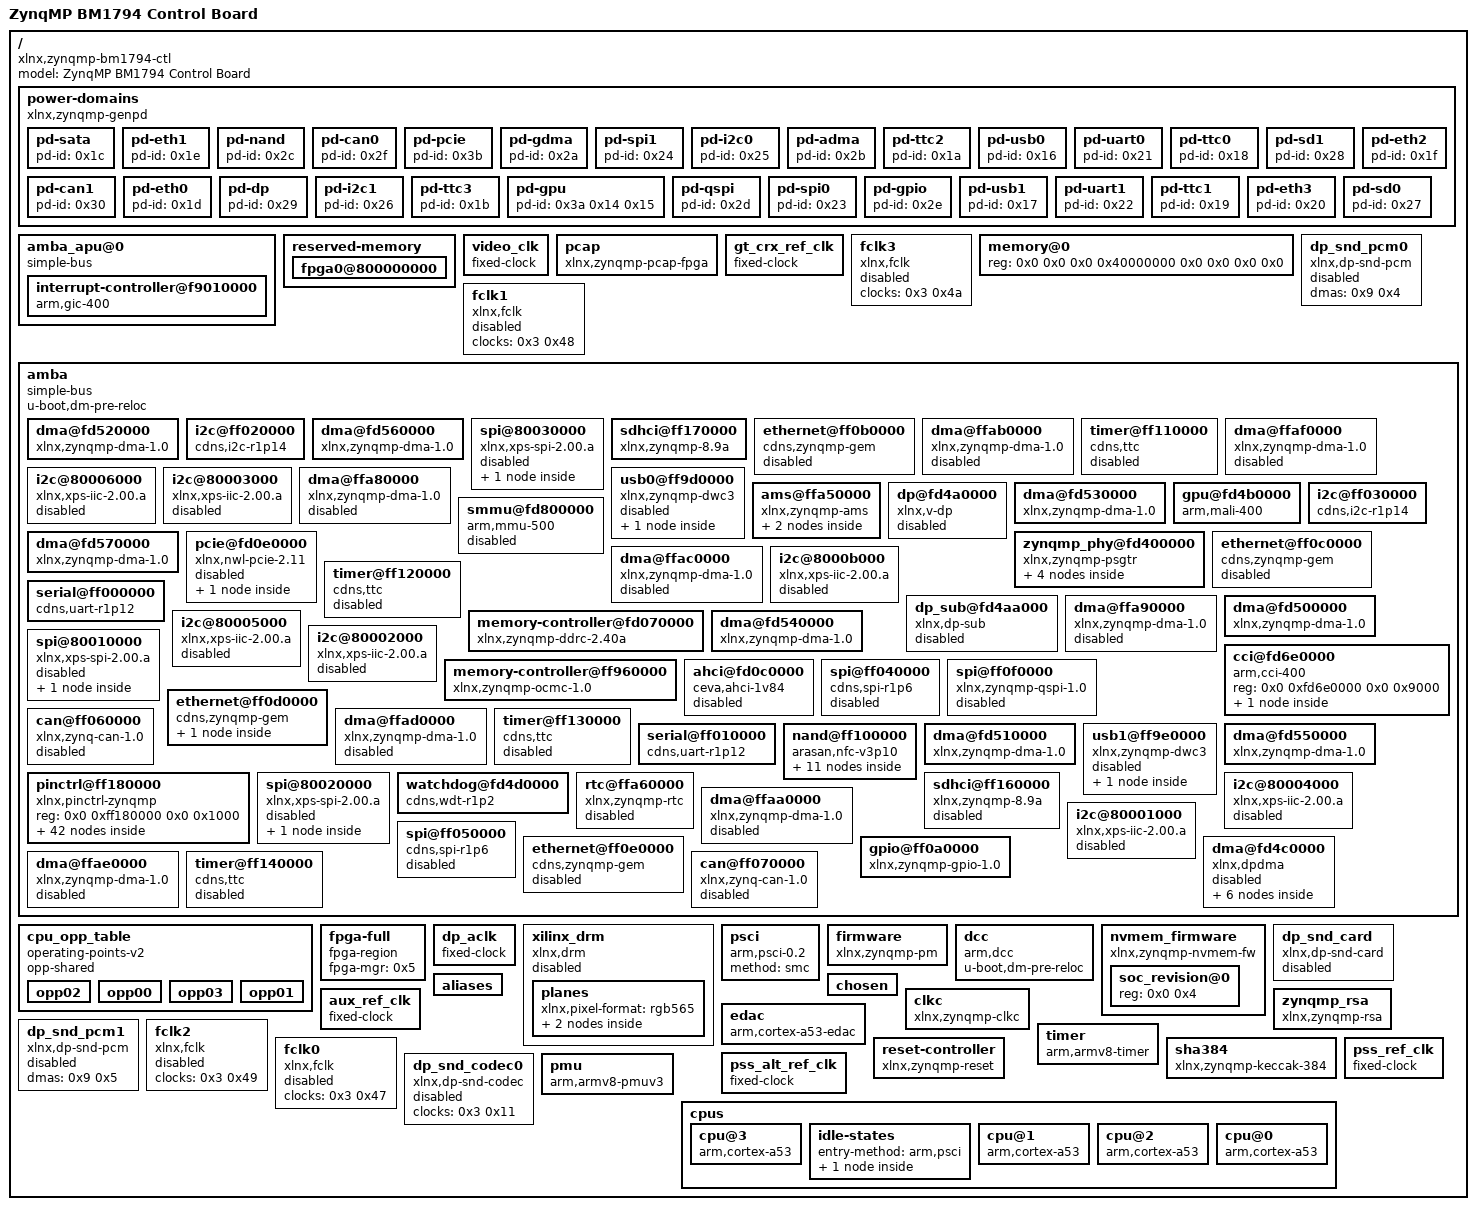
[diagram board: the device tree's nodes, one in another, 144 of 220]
/dts-v1/;

/ {
	compatible = "xlnx,zynqmp-bm1794-ctl", "xlnx,zynqmp";
	model = "ZynqMP BM1794 Control Board";
	#address-cells = <0x2>;
	#size-cells = <0x2>;

	power-domains {
		compatible = "xlnx,zynqmp-genpd";

		pd-sata {
			phandle = <0x28>;
			pd-id = <0x1c>;
			linux,phandle = <0x28>;
			#power-domain-cells = <0x0>;
		};

		pd-eth1 {
			phandle = <0x14>;
			pd-id = <0x1e>;
			linux,phandle = <0x14>;
			#power-domain-cells = <0x0>;
		};

		pd-nand {
			phandle = <0x12>;
			pd-id = <0x2c>;
			linux,phandle = <0x12>;
			#power-domain-cells = <0x0>;
		};

		pd-can0 {
			phandle = <0xc>;
			pd-id = <0x2f>;
			linux,phandle = <0xc>;
			#power-domain-cells = <0x0>;
		};

		pd-pcie {
			phandle = <0x24>;
			pd-id = <0x3b>;
			linux,phandle = <0x24>;
			#power-domain-cells = <0x0>;
		};

		pd-gdma {
			phandle = <0xf>;
			pd-id = <0x2a>;
			linux,phandle = <0xf>;
			#power-domain-cells = <0x0>;
		};

		pd-spi1 {
			phandle = <0x2f>;
			pd-id = <0x24>;
			linux,phandle = <0x2f>;
			#power-domain-cells = <0x0>;
		};

		pd-i2c0 {
			phandle = <0x1b>;
			pd-id = <0x25>;
			linux,phandle = <0x1b>;
			#power-domain-cells = <0x0>;
		};

		pd-adma {
			phandle = <0x11>;
			pd-id = <0x2b>;
			linux,phandle = <0x11>;
			#power-domain-cells = <0x0>;
		};

		pd-ttc2 {
			phandle = <0x32>;
			pd-id = <0x1a>;
			linux,phandle = <0x32>;
			#power-domain-cells = <0x0>;
		};

		pd-usb0 {
			phandle = <0x38>;
			pd-id = <0x16>;
			linux,phandle = <0x38>;
			#power-domain-cells = <0x0>;
		};

		pd-uart0 {
			phandle = <0x34>;
			pd-id = <0x21>;
			linux,phandle = <0x34>;
			#power-domain-cells = <0x0>;
		};

		pd-ttc0 {
			phandle = <0x30>;
			pd-id = <0x18>;
			linux,phandle = <0x30>;
			#power-domain-cells = <0x0>;
		};

		pd-sd1 {
			phandle = <0x2c>;
			pd-id = <0x28>;
			linux,phandle = <0x2c>;
			#power-domain-cells = <0x0>;
		};

		pd-eth2 {
			phandle = <0x15>;
			pd-id = <0x1f>;
			linux,phandle = <0x15>;
			#power-domain-cells = <0x0>;
		};

		pd-can1 {
			phandle = <0xd>;
			pd-id = <0x30>;
			linux,phandle = <0xd>;
			#power-domain-cells = <0x0>;
		};

		pd-eth0 {
			phandle = <0x13>;
			pd-id = <0x1d>;
			linux,phandle = <0x13>;
			#power-domain-cells = <0x0>;
		};

		pd-dp {
			phandle = <0x3a>;
			pd-id = <0x29>;
			linux,phandle = <0x3a>;
			#power-domain-cells = <0x0>;
		};

		pd-i2c1 {
			phandle = <0x1f>;
			pd-id = <0x26>;
			linux,phandle = <0x1f>;
			#power-domain-cells = <0x0>;
		};

		pd-ttc3 {
			phandle = <0x33>;
			pd-id = <0x1b>;
			linux,phandle = <0x33>;
			#power-domain-cells = <0x0>;
		};

		pd-gpu {
			phandle = <0x10>;
			pd-id = <0x3a 0x14 0x15>;
			linux,phandle = <0x10>;
			#power-domain-cells = <0x0>;
		};

		pd-qspi {
			phandle = <0x25>;
			pd-id = <0x2d>;
			linux,phandle = <0x25>;
			#power-domain-cells = <0x0>;
		};

		pd-spi0 {
			phandle = <0x2e>;
			pd-id = <0x23>;
			linux,phandle = <0x2e>;
			#power-domain-cells = <0x0>;
		};

		pd-gpio {
			phandle = <0x19>;
			pd-id = <0x2e>;
			linux,phandle = <0x19>;
			#power-domain-cells = <0x0>;
		};

		pd-usb1 {
			phandle = <0x39>;
			pd-id = <0x17>;
			linux,phandle = <0x39>;
			#power-domain-cells = <0x0>;
		};

		pd-uart1 {
			phandle = <0x36>;
			pd-id = <0x22>;
			linux,phandle = <0x36>;
			#power-domain-cells = <0x0>;
		};

		pd-ttc1 {
			phandle = <0x31>;
			pd-id = <0x19>;
			linux,phandle = <0x31>;
			#power-domain-cells = <0x0>;
		};

		pd-eth3 {
			phandle = <0x18>;
			pd-id = <0x20>;
			linux,phandle = <0x18>;
			#power-domain-cells = <0x0>;
		};

		pd-sd0 {
			phandle = <0x2a>;
			pd-id = <0x27>;
			linux,phandle = <0x2a>;
			#power-domain-cells = <0x0>;
		};
	};

	amba_apu@0 {
		compatible = "simple-bus";
		ranges = <0x0 0x0 0x0 0x0 0xffffffff>;
		#address-cells = <0x2>;
		#size-cells = <0x1>;

		interrupt-controller@f9010000 {
			compatible = "arm,gic-400", "arm,cortex-a15-gic";
			#interrupt-cells = <0x3>;
			interrupt-parent = <0x4>;
			interrupts = <0x1 0x9 0xf04>;
			phandle = <0x4>;
			reg = <0x0 0xf9010000 0x10000 0x0 0xf9020000 0x20000 0x0 0xf9040000 0x20000 0x0 0xf9060000 0x20000>;
			linux,phandle = <0x4>;
			interrupt-controller;
		};
	};

	reserved-memory {
		ranges;
		#address-cells = <0x2>;
		#size-cells = <0x2>;

		fpga0@800000000 {
			no-map;
			reg = <0x8 0x0 0x1 0x80000000>;
		};
	};

	video_clk {
		compatible = "fixed-clock";
		#clock-cells = <0x0>;
		phandle = <0x3d>;
		u-boot,dm-pre-reloc;
		clock-frequency = <0x19bfcc0>;
		linux,phandle = <0x3d>;
	};

	pcap {
		compatible = "xlnx,zynqmp-pcap-fpga";
		phandle = <0x5>;
		linux,phandle = <0x5>;
	};

	gt_crx_ref_clk {
		compatible = "fixed-clock";
		#clock-cells = <0x0>;
		phandle = <0x40>;
		u-boot,dm-pre-reloc;
		clock-frequency = <0x66ff300>;
		linux,phandle = <0x40>;
	};

	fclk3 {
		compatible = "xlnx,fclk";
		clocks = <0x3 0x4a>;
		status = "disabled";
	};

	memory@0 {
		device_type = "memory";
		reg = <0x0 0x0 0x0 0x40000000 0x0 0x0 0x0 0x0>;
	};

	dp_snd_pcm0 {
		compatible = "xlnx,dp-snd-pcm";
		status = "disabled";
		dma-names = "tx";
		phandle = <0x6>;
		dmas = <0x9 0x4>;
		linux,phandle = <0x6>;
	};

	fclk1 {
		compatible = "xlnx,fclk";
		clocks = <0x3 0x48>;
		status = "disabled";
	};

	amba {
		compatible = "simple-bus";
		ranges;
		#address-cells = <0x2>;
		#size-cells = <0x2>;
		u-boot,dm-pre-reloc;

		dma@fd520000 {
			power-domains = <0xf>;
			compatible = "xlnx,zynqmp-dma-1.0";
			clocks = <0x3 0x13 0x3 0x1f>;
			#stream-id-cells = <0x1>;
			clock-names = "clk_main", "clk_apb";
			xlnx,bus-width = <0x80>;
			status = "okay";
			interrupt-parent = <0x4>;
			interrupts = <0x0 0x7e 0x4>;
			reg = <0x0 0xfd520000 0x0 0x1000>;
			iommus = <0xe 0x14ea>;
		};

		i2c@ff020000 {
			power-domains = <0x1b>;
			compatible = "cdns,i2c-r1p14", "cdns,i2c-r1p10";
			clocks = <0x3 0x3d>;
			pinctrl-1 = <0x1d>;
			scl-gpios = <0x1e 0x22 0x0>;
			sda-gpios = <0x1e 0x23 0x0>;
			status = "okay";
			interrupt-parent = <0x4>;
			#address-cells = <0x1>;
			interrupts = <0x0 0x11 0x4>;
			#size-cells = <0x0>;
			reg = <0x0 0xff020000 0x0 0x1000>;
			clock-frequency = <0x61a80>;
			pinctrl-0 = <0x1c>;
			pinctrl-names = "default", "gpio";
		};

		dma@fd560000 {
			power-domains = <0xf>;
			compatible = "xlnx,zynqmp-dma-1.0";
			clocks = <0x3 0x13 0x3 0x1f>;
			#stream-id-cells = <0x1>;
			clock-names = "clk_main", "clk_apb";
			xlnx,bus-width = <0x80>;
			status = "okay";
			interrupt-parent = <0x4>;
			interrupts = <0x0 0x82 0x4>;
			reg = <0x0 0xfd560000 0x0 0x1000>;
			iommus = <0xe 0x14ee>;
		};

		spi@80030000 {
			compatible = "xlnx,xps-spi-2.00.a";
			clocks = <0x3 0x47 0x3 0x47 0x3 0x47>;
			bits-per-word = <0x8>;
			clock-names = "axi_clk", "axi4_clk", "spi_clk";
			fifo-size = <0x10>;
			status = "disabled";
			interrupt-parent = <0x4>;
			#address-cells = <0x1>;
			interrupts = <0x0 0x68 0x1>;
			#size-cells = <0x0>;
			reg = <0x0 0x80030000 0x0 0x10000>;
			num-cs = <0x1>;

			spidev@2 {
				compatible = "spidev";
				reg = <0x0>;
				spi-max-frequency = <0x7735940>;
			};
		};

		sdhci@ff170000 {
			power-domains = <0x2c>;
			compatible = "xlnx,zynqmp-8.9a", "arasan,sdhci-8.9a";
			clocks = <0x3 0x37 0x3 0x1f>;
			nvmem-cells = <0x26>;
			#stream-id-cells = <0x1>;
			clock-names = "clk_xin", "clk_ahb";
			status = "okay";
			interrupt-parent = <0x4>;
			interrupts = <0x0 0x31 0x4>;
			no-1-8-v;
			xlnx,mio_bank = <0x1>;
			xlnx,device_id = <0x1>;
			u-boot,dm-pre-reloc;
			reg = <0x0 0xff170000 0x0 0x1000>;
			iommus = <0xe 0x871>;
			pinctrl-0 = <0x2d>;
			pinctrl-names = "default";
			nvmem-cell-names = "soc_revision";
		};

		ethernet@ff0b0000 {
			power-domains = <0x13>;
			compatible = "cdns,zynqmp-gem";
			clocks = <0x3 0x2d 0x3 0x2d 0x3 0x31>;
			#stream-id-cells = <0x1>;
			clock-names = "pclk", "tx_clk", "hclk";
			status = "disabled";
			interrupt-parent = <0x4>;
			#address-cells = <0x1>;
			interrupts = <0x0 0x39 0x4 0x0 0x39 0x4>;
			#size-cells = <0x0>;
			reg = <0x0 0xff0b0000 0x0 0x1000>;
			iommus = <0xe 0x874>;
		};

		dma@ffab0000 {
			power-domains = <0x11>;
			compatible = "xlnx,zynqmp-dma-1.0";
			clocks = <0x3 0x44 0x3 0x1f>;
			#stream-id-cells = <0x1>;
			clock-names = "clk_main", "clk_apb";
			xlnx,bus-width = <0x40>;
			status = "disabled";
			interrupt-parent = <0x4>;
			interrupts = <0x0 0x50 0x4>;
			reg = <0x0 0xffab0000 0x0 0x1000>;
		};

		timer@ff110000 {
			power-domains = <0x30>;
			compatible = "cdns,ttc";
			timer-width = <0x20>;
			status = "disabled";
			interrupt-parent = <0x4>;
			interrupts = <0x0 0x24 0x4 0x0 0x25 0x4 0x0 0x26 0x4>;
			reg = <0x0 0xff110000 0x0 0x1000>;
		};

		dma@ffaf0000 {
			power-domains = <0x11>;
			compatible = "xlnx,zynqmp-dma-1.0";
			clocks = <0x3 0x44 0x3 0x1f>;
			#stream-id-cells = <0x1>;
			clock-names = "clk_main", "clk_apb";
			xlnx,bus-width = <0x40>;
			status = "disabled";
			interrupt-parent = <0x4>;
			interrupts = <0x0 0x54 0x4>;
			reg = <0x0 0xffaf0000 0x0 0x1000>;
		};

		i2c@80006000 {
			compatible = "xlnx,xps-iic-2.00.a";
			clocks = <0x3 0x47>;
			status = "disabled";
			interrupt-parent = <0x4>;
			interrupts = <0x0 0x5e 0x4>;
			reg = <0x0 0x80006000 0x0 0x1000>;
		};

		i2c@80003000 {
			compatible = "xlnx,xps-iic-2.00.a";
			clocks = <0x3 0x47>;
			status = "disabled";
			interrupt-parent = <0x4>;
			interrupts = <0x0 0x5b 0x4>;
			reg = <0x0 0x80003000 0x0 0x1000>;
		};

		dma@ffa80000 {
			power-domains = <0x11>;
			compatible = "xlnx,zynqmp-dma-1.0";
			clocks = <0x3 0x44 0x3 0x1f>;
			#stream-id-cells = <0x1>;
			clock-names = "clk_main", "clk_apb";
			xlnx,bus-width = <0x40>;
			status = "disabled";
			interrupt-parent = <0x4>;
			interrupts = <0x0 0x4d 0x4>;
			reg = <0x0 0xffa80000 0x0 0x1000>;
		};

		usb0@ff9d0000 {
			power-domains = <0x38>;
			compatible = "xlnx,zynqmp-dwc3";
			clocks = <0x3 0x20 0x3 0x22>;
			nvmem-cells = <0x26>;
			clock-names = "bus_clk", "ref_clk";
			ranges;
			status = "disabled";
			#address-cells = <0x2>;
			#size-cells = <0x2>;
			reg = <0x0 0xff9d0000 0x0 0x100>;
			nvmem-cell-names = "soc_revision";

			dwc3@fe200000 {
				snps,enable_guctl1_resume_quirk;
				compatible = "snps,dwc3";
				snps,enable_guctl1_ipd_quirk;
				#stream-id-cells = <0x1>;
				status = "disabled";
				interrupt-parent = <0x4>;
				interrupts = <0x0 0x41 0x4 0x0 0x45 0x4>;
				snps,xhci-stream-quirk;
				snps,refclk_fladj;
				reg = <0x0 0xfe200000 0x0 0x40000>;
				iommus = <0xe 0x860>;
				snps,quirk-frame-length-adjustment = <0x20>;
			};
		};

		ams@ffa50000 {
			compatible = "xlnx,zynqmp-ams";
			clocks = <0x3 0x46>;
			reg-names = "ams-base";
			#io-channel-cells = <0x1>;
			ranges;
			status = "okay";
			interrupt-parent = <0x4>;
			#address-cells = <0x2>;
			interrupts = <0x0 0x38 0x4>;
			#size-cells = <0x2>;
			reg = <0x0 0xffa50000 0x0 0x800>;
			interrupt-names = "ams-irq";

			ams_ps@ffa50800 {
				compatible = "xlnx,zynqmp-ams-ps";
				status = "okay";
				reg = <0x0 0xffa50800 0x0 0x400>;
			};

			ams_pl@ffa50c00 {
				compatible = "xlnx,zynqmp-ams-pl";
				status = "okay";
				reg = <0x0 0xffa50c00 0x0 0x400>;
			};
		};

		dp@fd4a0000 {
			xlnx,enable-ycrcb;
			power-domains = <0x3a>;
			compatible = "xlnx,v-dp";
			clocks = <0x3b 0x3 0x11>;
			xlnx,max-lanes = <0x2>;
			xlnx,max-pclock-frequency = <0x493e0>;
			xlnx,bpc = <0x8>;
			xlnx,colormetry = "rgb";
			xlnx,max-link-rate = <0x83d60>;
			clock-names = "aclk", "aud_clk";
			xlnx,audio-chan = <0x2>;
			status = "disabled";
			interrupt-parent = <0x4>;
			interrupts = <0x0 0x77 0x4>;
			phandle = <0xa>;
			xlnx,max-bpc = <0x10>;
			reg = <0x0 0xfd4a0000 0x0 0x1000>;
			xlnx,dp-version = "v1.2";
			linux,phandle = <0xa>;
			xlnx,dp-sub = <0xb>;
		};

		dma@fd530000 {
			power-domains = <0xf>;
			compatible = "xlnx,zynqmp-dma-1.0";
			clocks = <0x3 0x13 0x3 0x1f>;
			#stream-id-cells = <0x1>;
			clock-names = "clk_main", "clk_apb";
			xlnx,bus-width = <0x80>;
			status = "okay";
			interrupt-parent = <0x4>;
			interrupts = <0x0 0x7f 0x4>;
			reg = <0x0 0xfd530000 0x0 0x1000>;
			iommus = <0xe 0x14eb>;
		};

		gpu@fd4b0000 {
			power-domains = <0x10>;
			compatible = "arm,mali-400", "arm,mali-utgard";
			clocks = <0x3 0x18 0x3 0x19 0x3 0x1a>;
			clock-names = "gpu", "gpu_pp0", "gpu_pp1";
			status = "okay";
			interrupt-parent = <0x4>;
			interrupts = <0x0 0x84 0x4 0x0 0x84 0x4 0x0 0x84 0x4 0x0 0x84 0x4 0x0 0x84 0x4 0x0 0x84 0x4>;
			reg = <0x0 0xfd4b0000 0x0 0x10000>;
			interrupt-names = "IRQGP", "IRQGPMMU", "IRQPP0", "IRQPPMMU0", "IRQPP1", "IRQPPMMU1";
		};

		i2c@ff030000 {
			power-domains = <0x1f>;
			compatible = "cdns,i2c-r1p14", "cdns,i2c-r1p10";
			clocks = <0x3 0x3e>;
			pinctrl-1 = <0x21>;
			scl-gpios = <0x1e 0x24 0x0>;
			sda-gpios = <0x1e 0x25 0x0>;
			status = "okay";
			interrupt-parent = <0x4>;
			#address-cells = <0x1>;
			interrupts = <0x0 0x12 0x4>;
			#size-cells = <0x0>;
			reg = <0x0 0xff030000 0x0 0x1000>;
			clock-frequency = <0x61a80>;
			pinctrl-0 = <0x20>;
			pinctrl-names = "default", "gpio";
		};

		dma@fd570000 {
			power-domains = <0xf>;
			compatible = "xlnx,zynqmp-dma-1.0";
			clocks = <0x3 0x13 0x3 0x1f>;
			#stream-id-cells = <0x1>;
			clock-names = "clk_main", "clk_apb";
			xlnx,bus-width = <0x80>;
			status = "okay";
			interrupt-parent = <0x4>;
			interrupts = <0x0 0x83 0x4>;
			reg = <0x0 0xfd570000 0x0 0x1000>;
			iommus = <0xe 0x14ef>;
		};

		smmu@fd800000 {
			compatible = "arm,mmu-500";
			#iommu-cells = <0x1>;
			#global-interrupts = <0x1>;
			status = "disabled";
			interrupt-parent = <0x4>;
			interrupts = <0x0 0x9b 0x4 0x0 0x9b 0x4 0x0 0x9b 0x4 0x0 0x9b 0x4 0x0 0x9b 0x4 0x0 0x9b 0x4 0x0 0x9b 0x4 0x0 0x9b 0x4 0x0 0x9b 0x4 0x0 0x9b 0x4 0x0 0x9b 0x4 0x0 0x9b 0x4 0x0 0x9b 0x4 0x0 0x9b 0x4 0x0 0x9b 0x4 0x0 0x9b 0x4 0x0 0x9b 0x4>;
			phandle = <0xe>;
			reg = <0x0 0xfd800000 0x0 0x20000>;
			linux,phandle = <0xe>;
		};

		pcie@fd0e0000 {
			power-domains = <0x24>;
			compatible = "xlnx,nwl-pcie-2.11";
			clocks = <0x3 0x17>;
			reg-names = "breg", "pcireg", "cfg";
			device_type = "pci";
			interrupt-map-mask = <0x0 0x0 0x0 0x7>;
			ranges = <0x2000000 0x0 0xe0000000 0x0 0xe0000000 0x0 0x10000000 0x43000000 0x6 0x0 0x6 0x0 0x2 0x0>;
			status = "disabled";
			#interrupt-cells = <0x1>;
			bus-range = <0x0 0xff>;
			interrupt-parent = <0x4>;
			#address-cells = <0x3>;
			interrupts = <0x0 0x76 0x4 0x0 0x75 0x4 0x0 0x74 0x4 0x0 0x73 0x4 0x0 0x72 0x4>;
			interrupt-map = <0x0 0x0 0x0 0x1 0x23 0x1 0x0 0x0 0x0 0x2 0x23 0x2 0x0 0x0 0x0 0x3 0x23 0x3 0x0 0x0 0x0 0x4 0x23 0x4>;
			#size-cells = <0x2>;
			phandle = <0x22>;
			msi-parent = <0x22>;
			reg = <0x0 0xfd0e0000 0x0 0x1000 0x0 0xfd480000 0x0 0x1000 0x80 0x0 0x0 0x1000000>;
			linux,phandle = <0x22>;
			interrupt-names = "misc", "dummy", "intx", "msi1", "msi0";
			msi-controller;

			legacy-interrupt-controller {
				#interrupt-cells = <0x1>;
				#address-cells = <0x0>;
				phandle = <0x23>;
				linux,phandle = <0x23>;
				interrupt-controller;
			};
		};

		zynqmp_phy@fd400000 {
			compatible = "xlnx,zynqmp-psgtr";
			resets = <0x27 0x10 0x27 0x3b 0x27 0x3c 0x27 0x3d 0x27 0x3e 0x27 0x3f 0x27 0x40 0x27 0x3 0x27 0x1d 0x27 0x1e 0x27 0x1f 0x27 0x20>;
			nvmem-cells = <0x26>;
			reg-names = "serdes", "siou", "lpd";
			status = "okay";
			reg = <0x0 0xfd400000 0x0 0x40000 0x0 0xfd3d0000 0x0 0x1000 0x0 0xff5e0000 0x0 0x1000>;
			reset-names = "sata_rst", "usb0_crst", "usb1_crst", "usb0_hibrst", "usb1_hibrst", "usb0_apbrst", "usb1_apbrst", "dp_rst", "gem0_rst", "gem1_rst", "gem2_rst", "gem3_rst";
			nvmem-cell-names = "soc_revision";

			lane1 {
				#phy-cells = <0x4>;
			};

			lane2 {
				#phy-cells = <0x4>;
			};

			lane0 {
				phandle = <0x29>;
				#phy-cells = <0x4>;
				linux,phandle = <0x29>;
			};

			lane3 {
				#phy-cells = <0x4>;
			};
		};

		ethernet@ff0c0000 {
			power-domains = <0x14>;
			compatible = "cdns,zynqmp-gem";
			clocks = <0x3 0x2e 0x3 0x2e 0x3 0x32>;
			#stream-id-cells = <0x1>;
			clock-names = "pclk", "tx_clk", "hclk";
			status = "disabled";
			interrupt-parent = <0x4>;
			#address-cells = <0x1>;
			interrupts = <0x0 0x3b 0x4 0x0 0x3b 0x4>;
			#size-cells = <0x0>;
			reg = <0x0 0xff0c0000 0x0 0x1000>;
			iommus = <0xe 0x875>;
		};

		dma@ffac0000 {
			power-domains = <0x11>;
			compatible = "xlnx,zynqmp-dma-1.0";
			clocks = <0x3 0x44 0x3 0x1f>;
			#stream-id-cells = <0x1>;
			clock-names = "clk_main", "clk_apb";
			xlnx,bus-width = <0x40>;
			status = "disabled";
			interrupt-parent = <0x4>;
			interrupts = <0x0 0x51 0x4>;
			reg = <0x0 0xffac0000 0x0 0x1000>;
		};

		i2c@8000b000 {
			compatible = "xlnx,xps-iic-2.00.a";
			clocks = <0x3 0x47>;
			status = "disabled";
			interrupt-parent = <0x4>;
			interrupts = <0x0 0x6d 0x4>;
			reg = <0x0 0x8000b000 0x0 0x1000>;
		};

		timer@ff120000 {
			power-domains = <0x31>;
			compatible = "cdns,ttc";
			timer-width = <0x20>;
			status = "disabled";
			interrupt-parent = <0x4>;
			interrupts = <0x0 0x27 0x4 0x0 0x28 0x4 0x0 0x29 0x4>;
			reg = <0x0 0xff120000 0x0 0x1000>;
		};

		serial@ff000000 {
			power-domains = <0x34>;
			compatible = "cdns,uart-r1p12", "xlnx,xuartps";
			clocks = <0x3 0x38 0x3 0x1f>;
			clock-names = "uart_clk", "pclk";
			status = "okay";
			interrupt-parent = <0x4>;
			interrupts = <0x0 0x15 0x4>;
			u-boot,dm-pre-reloc;
			reg = <0x0 0xff000000 0x0 0x1000>;
			pinctrl-0 = <0x35>;
			pinctrl-names = "default";
		};

		dp_sub@fd4aa000 {
			power-domains = <0x3a>;
			compatible = "xlnx,dp-sub";
			reg-names = "blend", "av_buf", "aud";
			xlnx,gfx-fmt = "rgb565";
			status = "disabled";
			phandle = <0xb>;
			reg = <0x0 0xfd4aa000 0x0 0x1000 0x0 0xfd4ab000 0x0 0x1000 0x0 0xfd4ac000 0x0 0x1000>;
			xlnx,output-fmt = "rgb";
			linux,phandle = <0xb>;
			xlnx,vid-fmt = "yuyv";
		};

		dma@ffa90000 {
			power-domains = <0x11>;
			compatible = "xlnx,zynqmp-dma-1.0";
			clocks = <0x3 0x44 0x3 0x1f>;
			#stream-id-cells = <0x1>;
			clock-names = "clk_main", "clk_apb";
			xlnx,bus-width = <0x40>;
			status = "disabled";
			interrupt-parent = <0x4>;
			interrupts = <0x0 0x4e 0x4>;
			reg = <0x0 0xffa90000 0x0 0x1000>;
		};

		memory-controller@fd070000 {
			compatible = "xlnx,zynqmp-ddrc-2.40a";
			interrupt-parent = <0x4>;
			interrupts = <0x0 0x70 0x4>;
			reg = <0x0 0xfd070000 0x0 0x30000>;
		};

		dma@fd500000 {
			power-domains = <0xf>;
			compatible = "xlnx,zynqmp-dma-1.0";
			clocks = <0x3 0x13 0x3 0x1f>;
			#stream-id-cells = <0x1>;
			clock-names = "clk_main", "clk_apb";
			xlnx,bus-width = <0x80>;
			status = "okay";
			interrupt-parent = <0x4>;
			interrupts = <0x0 0x7c 0x4>;
			reg = <0x0 0xfd500000 0x0 0x1000>;
			iommus = <0xe 0x14e8>;
		};

		i2c@80005000 {
			compatible = "xlnx,xps-iic-2.00.a";
			clocks = <0x3 0x47>;
			status = "disabled";
			interrupt-parent = <0x4>;
			interrupts = <0x0 0x5d 0x4>;
			reg = <0x0 0x80005000 0x0 0x1000>;
		};

		dma@fd540000 {
			power-domains = <0xf>;
			compatible = "xlnx,zynqmp-dma-1.0";
			clocks = <0x3 0x13 0x3 0x1f>;
			#stream-id-cells = <0x1>;
			clock-names = "clk_main", "clk_apb";
			xlnx,bus-width = <0x80>;
			status = "okay";
			interrupt-parent = <0x4>;
			interrupts = <0x0 0x80 0x4>;
			reg = <0x0 0xfd540000 0x0 0x1000>;
			iommus = <0xe 0x14ec>;
		};

		i2c@80002000 {
			compatible = "xlnx,xps-iic-2.00.a";
			clocks = <0x3 0x47>;
			status = "disabled";
			interrupt-parent = <0x4>;
			interrupts = <0x0 0x5a 0x4>;
			reg = <0x0 0x80002000 0x0 0x1000>;
		};

		spi@80010000 {
			compatible = "xlnx,xps-spi-2.00.a";
			clocks = <0x3 0x47 0x3 0x47 0x3 0x47>;
			bits-per-word = <0x8>;
			clock-names = "axi_clk", "axi4_clk", "spi_clk";
			fifo-size = <0x10>;
			status = "disabled";
			interrupt-parent = <0x4>;
			#address-cells = <0x1>;
			interrupts = <0x0 0x5f 0x1>;
			#size-cells = <0x0>;
			reg = <0x0 0x80010000 0x0 0x10000>;
			num-cs = <0x1>;

			spidev@0 {
				compatible = "spidev";
				reg = <0x0>;
				spi-max-frequency = <0x7735940>;
			};
		};

		memory-controller@ff960000 {
			compatible = "xlnx,zynqmp-ocmc-1.0";
			interrupt-parent = <0x4>;
			interrupts = <0x0 0xa 0x4>;
			reg = <0x0 0xff960000 0x0 0x1000>;
		};

		cci@fd6e0000 {
			compatible = "arm,cci-400";
			ranges = <0x0 0x0 0xfd6e0000 0x10000>;
			#address-cells = <0x1>;
			#size-cells = <0x1>;
			reg = <0x0 0xfd6e0000 0x0 0x9000>;

			pmu@9000 {
				compatible = "arm,cci-400-pmu,r1";
				interrupt-parent = <0x4>;
				interrupts = <0x0 0x7b 0x4 0x0 0x7b 0x4 0x0 0x7b 0x4 0x0 0x7b 0x4 0x0 0x7b 0x4>;
				reg = <0x9000 0x5000>;
			};
		};

		ahci@fd0c0000 {
			ceva,p0-cominit-params = <0x18401828>;
			power-domains = <0x28>;
			compatible = "ceva,ahci-1v84";
			clocks = <0x3 0x16>;
			ceva,p1-comwake-params = <0x614080e>;
			#stream-id-cells = <0x4>;
			ceva,p0-retry-params = <0x96a43ffc>;
			ceva,p0-burst-params = <0x13084a06>;
			phy-names = "sata-phy";
			status = "disabled";
			interrupt-parent = <0x4>;
			ceva,p1-retry-params = <0x96a43ffc>;
			ceva,p1-burst-params = <0x13084a06>;
			interrupts = <0x0 0x85 0x4>;
			ceva,p0-comwake-params = <0x614080e>;
			ceva,p1-cominit-params = <0x18401828>;
			phys = <0x29 0x1 0x0 0x0 0x7735940>;
			reg = <0x0 0xfd0c0000 0x0 0x2000>;
			iommus = <0xe 0x4c0 0xe 0x4c1 0xe 0x4c2 0xe 0x4c3>;
		};

		spi@ff040000 {
			power-domains = <0x2e>;
			compatible = "cdns,spi-r1p6";
			clocks = <0x3 0x3a 0x3 0x1f>;
			clock-names = "ref_clk", "pclk";
			status = "disabled";
			interrupt-parent = <0x4>;
			#address-cells = <0x1>;
			interrupts = <0x0 0x13 0x4>;
			#size-cells = <0x0>;
			reg = <0x0 0xff040000 0x0 0x1000>;
		};

		spi@ff0f0000 {
			power-domains = <0x25>;
			compatible = "xlnx,zynqmp-qspi-1.0";
			clocks = <0x3 0x35 0x3 0x1f>;
			#stream-id-cells = <0x1>;
			clock-names = "ref_clk", "pclk";
			status = "disabled";
			interrupt-parent = <0x4>;
			#address-cells = <0x1>;
			interrupts = <0x0 0xf 0x4>;
			#size-cells = <0x0>;
			u-boot,dm-pre-reloc;
			reg = <0x0 0xff0f0000 0x0 0x1000 0x0 0xc0000000 0x0 0x8000000>;
			iommus = <0xe 0x873>;
			num-cs = <0x1>;
		};

		ethernet@ff0d0000 {
			phy-handle = <0x16>;
			power-domains = <0x15>;
			compatible = "cdns,zynqmp-gem";
			clocks = <0x3 0x2f 0x3 0x2f 0x3 0x33>;
			#stream-id-cells = <0x1>;
			clock-names = "pclk", "tx_clk", "hclk";
			status = "okay";
			interrupt-parent = <0x4>;
			#address-cells = <0x1>;
			interrupts = <0x0 0x3d 0x4 0x0 0x3d 0x4>;
			#size-cells = <0x0>;
			reg = <0x0 0xff0d0000 0x0 0x1000>;
			phy-mode = "rgmii-id";
			iommus = <0xe 0x876>;
			pinctrl-0 = <0x17>;
			pinctrl-names = "default";

			phy@0 {
				ti,rxctrl-strap-worka;
				ti,rx-internal-delay = <0x8>;
				phandle = <0x16>;
				ti,fifo-depth = <0x1>;
				reg = <0x0>;
				ti,tx-internal-delay = <0xa>;
				linux,phandle = <0x16>;
			};
		};

		dma@ffad0000 {
			power-domains = <0x11>;
			compatible = "xlnx,zynqmp-dma-1.0";
			clocks = <0x3 0x44 0x3 0x1f>;
			#stream-id-cells = <0x1>;
			clock-names = "clk_main", "clk_apb";
			xlnx,bus-width = <0x40>;
			status = "disabled";
			interrupt-parent = <0x4>;
			interrupts = <0x0 0x52 0x4>;
			reg = <0x0 0xffad0000 0x0 0x1000>;
		};

		timer@ff130000 {
			power-domains = <0x32>;
			compatible = "cdns,ttc";
			timer-width = <0x20>;
			status = "disabled";
			interrupt-parent = <0x4>;
			interrupts = <0x0 0x2a 0x4 0x0 0x2b 0x4 0x0 0x2c 0x4>;
			reg = <0x0 0xff130000 0x0 0x1000>;
		};

		serial@ff010000 {
			power-domains = <0x36>;
			compatible = "cdns,uart-r1p12", "xlnx,xuartps";
			clocks = <0x3 0x39 0x3 0x1f>;
			clock-names = "uart_clk", "pclk";
			status = "okay";
			interrupt-parent = <0x4>;
			interrupts = <0x0 0x16 0x4>;
			u-boot,dm-pre-reloc;
			reg = <0x0 0xff010000 0x0 0x1000>;
			pinctrl-0 = <0x37>;
			pinctrl-names = "default";
		};

		can@ff060000 {
			power-domains = <0xc>;
			compatible = "xlnx,zynq-can-1.0";
			clocks = <0x3 0x3f 0x3 0x1f>;
			tx-fifo-depth = <0x40>;
			clock-names = "can_clk", "pclk";
			status = "disabled";
			interrupt-parent = <0x4>;
			interrupts = <0x0 0x17 0x4>;
			reg = <0x0 0xff060000 0x0 0x1000>;
			rx-fifo-depth = <0x40>;
		};

		nand@ff100000 {
			power-domains = <0x12>;
			compatible = "arasan,nfc-v3p10";
			clocks = <0x3 0x3c 0x3 0x1f>;
			#stream-id-cells = <0x1>;
			clock-names = "clk_sys", "clk_flash";
			status = "okay";
			interrupt-parent = <0x4>;
			#address-cells = <0x1>;
			interrupts = <0x0 0xe 0x4>;
			#size-cells = <0x0>;
			arasan,has-mdma;
			reg = <0x0 0xff100000 0x0 0x1000>;
			iommus = <0xe 0x872>;

			nand@0 {
				#address-cells = <0x2>;
				#size-cells = <0x1>;
				reg = <0x0>;

				partition@0 {
					label = "nand-fsbl-uboot";
					reg = <0x0 0x0 0x800000>;
				};

				partition@9 {
					label = "nand-uramdisk-bak";
					reg = <0x0 0x6000000 0x2000000>;
				};

				partition@7 {
					label = "nand-config";
					reg = <0x0 0x4b00000 0x800000>;
				};

				partition@5 {
					label = "device-tree";
					reg = <0x0 0x2a00000 0x100000>;
				};

				partition@3 {
					label = "nand-fsbl-reserve";
					reg = <0x0 0x1800000 0x200000>;
				};

				partition@1 {
					label = "nand-fsbl-uboot";
					reg = <0x0 0x800000 0x800000>;
				};

				partition@8 {
					label = "nand-reserve";
					reg = <0x0 0x5300000 0xd00000>;
				};

				partition@6 {
					label = "nand-uramdisk-image";
					reg = <0x0 0x2b00000 0x2000000>;
				};

				partition@4 {
					label = "nand-linux-uimage";
					reg = <0x0 0x1a00000 0x1000000>;
				};

				partition@2 {
					label = "nand-fsbl-uboot";
					reg = <0x0 0x1000000 0x800000>;
				};
			};
		};

		dma@fd510000 {
			power-domains = <0xf>;
			compatible = "xlnx,zynqmp-dma-1.0";
			clocks = <0x3 0x13 0x3 0x1f>;
			#stream-id-cells = <0x1>;
			clock-names = "clk_main", "clk_apb";
			xlnx,bus-width = <0x80>;
			status = "okay";
			interrupt-parent = <0x4>;
			interrupts = <0x0 0x7d 0x4>;
			reg = <0x0 0xfd510000 0x0 0x1000>;
			iommus = <0xe 0x14e9>;
		};

		usb1@ff9e0000 {
			power-domains = <0x39>;
			compatible = "xlnx,zynqmp-dwc3";
			clocks = <0x3 0x21 0x3 0x22>;
			nvmem-cells = <0x26>;
			clock-names = "bus_clk", "ref_clk";
			ranges;
			status = "disabled";
			#address-cells = <0x2>;
			#size-cells = <0x2>;
			reg = <0x0 0xff9e0000 0x0 0x100>;
			nvmem-cell-names = "soc_revision";

			dwc3@fe300000 {
				snps,enable_guctl1_resume_quirk;
				compatible = "snps,dwc3";
				snps,enable_guctl1_ipd_quirk;
				#stream-id-cells = <0x1>;
				status = "disabled";
				interrupt-parent = <0x4>;
				interrupts = <0x0 0x46 0x4 0x0 0x4a 0x4>;
				snps,xhci-stream-quirk;
				snps,refclk_fladj;
				reg = <0x0 0xfe300000 0x0 0x40000>;
				iommus = <0xe 0x861>;
				snps,quirk-frame-length-adjustment = <0x20>;
			};
		};

		dma@fd550000 {
			power-domains = <0xf>;
			compatible = "xlnx,zynqmp-dma-1.0";
			clocks = <0x3 0x13 0x3 0x1f>;
			#stream-id-cells = <0x1>;
			clock-names = "clk_main", "clk_apb";
			xlnx,bus-width = <0x80>;
			status = "okay";
			interrupt-parent = <0x4>;
			interrupts = <0x0 0x81 0x4>;
			reg = <0x0 0xfd550000 0x0 0x1000>;
			iommus = <0xe 0x14ed>;
		};

		pinctrl@ff180000 {
			compatible = "xlnx,pinctrl-zynqmp";
			status = "okay";
			reg = <0x0 0xff180000 0x0 0x1000>;

			uart0-default {
				phandle = <0x35>;
				linux,phandle = <0x35>;

				mux {
					groups = "uart0_7_grp";
					function = "uart0";
				};

				conf {
					slew-rate = <0x1>;
					groups = "uart0_7_grp";
					io-standard = <0x1>;
				};

				conf-tx {
					pins = "MIO31";
					bias-disable;
				};

				conf-rx {
					pins = "MIO30";
					bias-high-impedance;
				};
			};

			sdhci1-default {
				phandle = <0x2d>;
				linux,phandle = <0x2d>;

				conf-wp {
					slew-rate = <0x1>;
					groups = "sdio1_0_wp_grp";
					bias-high-impedance;
					bias-pull-up;
					io-standard = <0x0>;
				};

				conf-cd {
					slew-rate = <0x1>;
					groups = "sdio1_0_cd_grp";
					bias-high-impedance;
					bias-pull-up;
					io-standard = <0x0>;
				};

				mux {
					groups = "sdio1_4bit_0_1_grp";
					function = "sdio1";
				};

				mux-wp {
					groups = "sdio1_0_wp_grp";
					function = "sdio1_wp";
				};

				mux-cd {
					groups = "sdio1_0_cd_grp";
					function = "sdio1_cd";
				};

				conf {
					bias-disable;
					slew-rate = <0x1>;
					groups = "sdio1_4bit_0_1_grp";
					io-standard = <0x0>;
				};
			};

			gem2-default {
				phandle = <0x17>;
				linux,phandle = <0x17>;

				mux-mdio {
					groups = "mdio2_0_grp";
					function = "mdio2";
				};

				conf-mdio {
					bias-disable;
					slew-rate = <0x1>;
					groups = "mdio2_0_grp";
					io-standard = <0x0>;
				};

				mux {
					groups = "ethernet2_0_grp";
					function = "ethernet2";
				};

				conf {
					slew-rate = <0x1>;
					groups = "ethernet2_0_grp";
					io-standard = <0x0>;
				};

				conf-tx {
					low-power-enable;
					pins = "MIO56", "MIO57", "MIO58", "MIO59", "MIO50", "MIO51";
					bias-disable;
				};

				conf-rx {
					pins = "MIO52", "MIO53", "MIO54", "MIO55", "MIO56", "MIO57";
					low-power-disable;
					bias-high-impedance;
				};
			};

			i2c1-default {
				phandle = <0x20>;
				linux,phandle = <0x20>;

				mux {
					groups = "i2c1_9_grp";
					function = "i2c1";
				};

				conf {
					slew-rate = <0x1>;
					groups = "i2c1_9_grp";
					bias-pull-up;
					io-standard = <0x1>;
				};
			};

			uart1-default {
				phandle = <0x37>;
				linux,phandle = <0x37>;

				mux {
					groups = "uart1_8_grp";
					function = "uart1";
				};

				conf {
					slew-rate = <0x1>;
					groups = "uart1_8_grp";
					io-standard = <0x1>;
				};

				conf-tx {
					pins = "MIO32";
					bias-disable;
				};

				conf-rx {
					pins = "MIO33";
					bias-high-impedance;
				};
			};

			i2c1-gpio {
				phandle = <0x21>;
				linux,phandle = <0x21>;

				mux {
					groups = "gpio0_35_grp", "gpio0_36_grp";
					function = "gpio1";
				};

				conf {
					slew-rate = <0x1>;
					groups = "gpio0_35_grp", "gpio0_36_grp";
					io-standard = <0x1>;
				};
			};

			gpio-default {
				phandle = <0x1a>;
				linux,phandle = <0x1a>;

				conf-sw {
					slew-rate = <0x1>;
					groups = "gpio0_26_grp", "gpio0_27_grp", "gpio0_28_grp", "gpio0_29_grp", "gpio0_38_grp", "gpio0_39_grp", "gpio0_40_grp", "gpio0_41_grp", "gpio0_42_grp", "gpio0_64_grp", "gpio0_65_grp", "gpio0_66_grp", "gpio0_67_grp", "gpio0_68_grp", "gpio0_69_grp", "gpio0_70_grp", "gpio0_71_grp", "gpio0_72_grp", "gpio0_73_grp", "gpio0_74_grp", "gpio0_75_grp";
					io-standard = <0x1>;
				};

				mux-sw {
					groups = "gpio0_26_grp", "gpio0_27_grp", "gpio0_28_grp", "gpio0_29_grp", "gpio0_38_grp", "gpio0_39_grp", "gpio0_40_grp", "gpio0_41_grp", "gpio0_42_grp", "gpio0_64_grp", "gpio0_65_grp", "gpio0_66_grp", "gpio0_67_grp", "gpio0_68_grp", "gpio0_69_grp", "gpio0_70_grp", "gpio0_71_grp", "gpio0_72_grp", "gpio0_73_grp", "gpio0_74_grp", "gpio0_75_grp";
					function = "gpio0";
				};
			};

			i2c0-gpio {
				phandle = <0x1d>;
				linux,phandle = <0x1d>;

				mux {
					groups = "gpio0_33_grp", "gpio0_34_grp";
					function = "gpio1";
				};

				conf {
					slew-rate = <0x1>;
					groups = "gpio0_33_grp", "gpio0_34_grp";
					io-standard = <0x1>;
				};
			};

			sdhci0-default {
				phandle = <0x2b>;
				linux,phandle = <0x2b>;

				mux {
					groups = "sdio0_0_grp";
					function = "sdio0";
				};

				conf {
					bias-disable;
					slew-rate = <0x1>;
					groups = "sdio0_0_grp";
					io-standard = <0x1>;
				};
			};

			i2c0-default {
				phandle = <0x1c>;
				linux,phandle = <0x1c>;

				mux {
					groups = "i2c0_8_grp";
					function = "i2c1";
				};

				conf {
					slew-rate = <0x1>;
					groups = "i2c0_8_grp";
					bias-pull-up;
					io-standard = <0x1>;
				};
			};
		};

		spi@80020000 {
			compatible = "xlnx,xps-spi-2.00.a";
			clocks = <0x3 0x47 0x3 0x47 0x3 0x47>;
			bits-per-word = <0x8>;
			clock-names = "axi_clk", "axi4_clk", "spi_clk";
			fifo-size = <0x10>;
			status = "disabled";
			interrupt-parent = <0x4>;
			#address-cells = <0x1>;
			interrupts = <0x0 0x60 0x1>;
			#size-cells = <0x0>;
			reg = <0x0 0x80020000 0x0 0x10000>;
			num-cs = <0x1>;

			spidev@1 {
				compatible = "spidev";
				reg = <0x0>;
				spi-max-frequency = <0x7735940>;
			};
		};

		watchdog@fd4d0000 {
			reset-on-timeout;
			compatible = "cdns,wdt-r1p2";
			clocks = <0x3 0x4b>;
			status = "okay";
			interrupt-parent = <0x4>;
			interrupts = <0x0 0x71 0x1>;
			reg = <0x0 0xfd4d0000 0x0 0x1000>;
			timeout-sec = <0x1e>;
		};

		rtc@ffa60000 {
			compatible = "xlnx,zynqmp-rtc";
			status = "disabled";
			interrupt-parent = <0x4>;
			interrupts = <0x0 0x1a 0x4 0x0 0x1b 0x4>;
			calibration = <0x8000>;
			reg = <0x0 0xffa60000 0x0 0x100>;
			interrupt-names = "alarm", "sec";
		};

		sdhci@ff160000 {
			power-domains = <0x2a>;
			compatible = "xlnx,zynqmp-8.9a", "arasan,sdhci-8.9a";
			clocks = <0x3 0x36 0x3 0x1f>;
			nvmem-cells = <0x26>;
			#stream-id-cells = <0x1>;
			clock-names = "clk_xin", "clk_ahb";
			status = "disabled";
			interrupt-parent = <0x4>;
			interrupts = <0x0 0x30 0x4>;
			no-1-8-v;
			xlnx,mio_bank = <0x0>;
			xlnx,device_id = <0x0>;
			u-boot,dm-pre-reloc;
			reg = <0x0 0xff160000 0x0 0x1000>;
			iommus = <0xe 0x870>;
			pinctrl-0 = <0x2b>;
			pinctrl-names = "default";
			nvmem-cell-names = "soc_revision";
		};

		i2c@80004000 {
			compatible = "xlnx,xps-iic-2.00.a";
			clocks = <0x3 0x47>;
			status = "disabled";
			interrupt-parent = <0x4>;
			interrupts = <0x0 0x5c 0x4>;
			reg = <0x0 0x80004000 0x0 0x1000>;
		};

		dma@ffaa0000 {
			power-domains = <0x11>;
			compatible = "xlnx,zynqmp-dma-1.0";
			clocks = <0x3 0x44 0x3 0x1f>;
			#stream-id-cells = <0x1>;
			clock-names = "clk_main", "clk_apb";
			xlnx,bus-width = <0x40>;
			status = "disabled";
			interrupt-parent = <0x4>;
			interrupts = <0x0 0x4f 0x4>;
			reg = <0x0 0xffaa0000 0x0 0x1000>;
		};

		i2c@80001000 {
			compatible = "xlnx,xps-iic-2.00.a";
			clocks = <0x3 0x47>;
			status = "disabled";
			interrupt-parent = <0x4>;
			interrupts = <0x0 0x59 0x4>;
			reg = <0x0 0x80001000 0x0 0x1000>;
		};

		spi@ff050000 {
			power-domains = <0x2f>;
			compatible = "cdns,spi-r1p6";
			clocks = <0x3 0x3b 0x3 0x1f>;
			clock-names = "ref_clk", "pclk";
			status = "disabled";
			interrupt-parent = <0x4>;
			#address-cells = <0x1>;
			interrupts = <0x0 0x14 0x4>;
			#size-cells = <0x0>;
			reg = <0x0 0xff050000 0x0 0x1000>;
		};

		ethernet@ff0e0000 {
			power-domains = <0x18>;
			compatible = "cdns,zynqmp-gem";
			clocks = <0x3 0x1f 0x3 0x34 0x3 0x30 0x3 0x34>;
			#stream-id-cells = <0x1>;
			clock-names = "pclk", "hclk", "tx_clk", "rx_clk";
			status = "disabled";
			interrupt-parent = <0x4>;
			#address-cells = <0x1>;
			interrupts = <0x0 0x3f 0x4 0x0 0x3f 0x4>;
			#size-cells = <0x0>;
			reg = <0x0 0xff0e0000 0x0 0x1000>;
			iommus = <0xe 0x877>;
		};

		gpio@ff0a0000 {
			power-domains = <0x19>;
			compatible = "xlnx,zynqmp-gpio-1.0";
			clocks = <0x3 0x1f>;
			gpio-controller;
			status = "okay";
			#interrupt-cells = <0x2>;
			interrupt-parent = <0x4>;
			interrupts = <0x0 0x10 0x4>;
			phandle = <0x1e>;
			reg = <0x0 0xff0a0000 0x0 0x1000>;
			#gpio-cells = <0x2>;
			pinctrl-0 = <0x1a>;
			linux,phandle = <0x1e>;
			pinctrl-names = "default";
			interrupt-controller;
		};

		dma@fd4c0000 {
			#dma-cells = <0x1>;
			power-domains = <0x3a>;
			compatible = "xlnx,dpdma";
			clocks = <0x3 0x14>;
			clock-names = "axi_clk";
			dma-channels = <0x6>;
			status = "disabled";
			interrupt-parent = <0x4>;
			interrupts = <0x0 0x7a 0x4>;
			phandle = <0x9>;
			reg = <0x0 0xfd4c0000 0x0 0x1000>;
			linux,phandle = <0x9>;

			dma-audio0channel {
				compatible = "xlnx,audio0";
			};

			dma-graphicschannel {
				compatible = "xlnx,graphics";
			};

			dma-video2channel {
				compatible = "xlnx,video2";
			};

			dma-video1channel {
				compatible = "xlnx,video1";
			};

			dma-video0channel {
				compatible = "xlnx,video0";
			};

			dma-audio1channel {
				compatible = "xlnx,audio1";
			};
		};

		dma@ffae0000 {
			power-domains = <0x11>;
			compatible = "xlnx,zynqmp-dma-1.0";
			clocks = <0x3 0x44 0x3 0x1f>;
			#stream-id-cells = <0x1>;
			clock-names = "clk_main", "clk_apb";
			xlnx,bus-width = <0x40>;
			status = "disabled";
			interrupt-parent = <0x4>;
			interrupts = <0x0 0x53 0x4>;
			reg = <0x0 0xffae0000 0x0 0x1000>;
		};

		timer@ff140000 {
			power-domains = <0x33>;
			compatible = "cdns,ttc";
			timer-width = <0x20>;
			status = "disabled";
			interrupt-parent = <0x4>;
			interrupts = <0x0 0x2d 0x4 0x0 0x2e 0x4 0x0 0x2f 0x4>;
			reg = <0x0 0xff140000 0x0 0x1000>;
		};

		can@ff070000 {
			power-domains = <0xd>;
			compatible = "xlnx,zynq-can-1.0";
			clocks = <0x3 0x40 0x3 0x1f>;
			tx-fifo-depth = <0x40>;
			clock-names = "can_clk", "pclk";
			status = "disabled";
			interrupt-parent = <0x4>;
			interrupts = <0x0 0x18 0x4>;
			reg = <0x0 0xff070000 0x0 0x1000>;
			rx-fifo-depth = <0x40>;
		};
	};

	cpu_opp_table {
		compatible = "operating-points-v2";
		phandle = <0x1>;
		opp-shared;
		linux,phandle = <0x1>;

		opp02 {
			opp-microvolt = <0xf4240>;
			opp-hz = <0x0 0x17d783fc>;
			clock-latency-ns = <0x7a120>;
		};

		opp00 {
			opp-microvolt = <0xf4240>;
			opp-hz = <0x0 0x47868bf4>;
			clock-latency-ns = <0x7a120>;
		};

		opp03 {
			opp-microvolt = <0xf4240>;
			opp-hz = <0x0 0x11e1a2fd>;
			clock-latency-ns = <0x7a120>;
		};

		opp01 {
			opp-microvolt = <0xf4240>;
			opp-hz = <0x0 0x23c345fa>;
			clock-latency-ns = <0x7a120>;
		};
	};

	fpga-full {
		compatible = "fpga-region";
		fpga-mgr = <0x5>;
		#address-cells = <0x2>;
		#size-cells = <0x2>;
	};

	dp_aclk {
		compatible = "fixed-clock";
		#clock-cells = <0x0>;
		phandle = <0x3b>;
		clock-accuracy = <0x64>;
		clock-frequency = <0x5f5e100>;
		linux,phandle = <0x3b>;
	};

	xilinx_drm {
		compatible = "xlnx,drm";
		clocks = <0x3 0x10>;
		xlnx,connector-type = "DisplayPort";
		status = "disabled";
		xlnx,encoder-slave = <0xa>;
		xlnx,dp-sub = <0xb>;

		planes {
			xlnx,pixel-format = "rgb565";

			plane0 {
				dma-names = "dma0";
				dmas = <0x9 0x3>;
			};

			plane1 {
				dma-names = "dma0", "dma1", "dma2";
				dmas = <0x9 0x0 0x9 0x1 0x9 0x2>;
			};
		};
	};

	psci {
		compatible = "arm,psci-0.2";
		method = "smc";
	};

	firmware {
		compatible = "xlnx,zynqmp-pm";
		interrupt-parent = <0x4>;
		interrupts = <0x0 0x23 0x4>;
		method = "smc";
	};

	dcc {
		compatible = "arm,dcc";
		status = "okay";
		u-boot,dm-pre-reloc;
	};

	nvmem_firmware {
		compatible = "xlnx,zynqmp-nvmem-fw";
		#address-cells = <0x1>;
		#size-cells = <0x1>;

		soc_revision@0 {
			phandle = <0x26>;
			reg = <0x0 0x4>;
			linux,phandle = <0x26>;
		};
	};

	dp_snd_card {
		compatible = "xlnx,dp-snd-card";
		xlnx,dp-snd-pcm = <0x6 0x7>;
		xlnx,dp-snd-codec = <0x8>;
		status = "disabled";
	};

	aliases {
		i2c1 = "/amba/i2c@ff030000";
		gpio0 = "/amba/gpio@ff0a0000";
		mmc1 = "/amba/sdhci@ff170000";
		ethernet0 = "/amba/ethernet@ff0d0000";
		serial1 = "/amba/serial@ff000000";
		nand = "/amba/nand@ff100000";
		i2c0 = "/amba/i2c@ff020000";
		mmc0 = "/amba/sdhci@ff160000";
		serial0 = "/amba/serial@ff010000";
	};

	chosen {
		stdout-path = "serial0:115200n8";
		bootargs = "earlycon clk_ignore_unused mem=496M console=ttyPS0,115200 ramdisk_size=33554432 root=/dev/ram rw earlyprintk";
		linux,initrd-start = <0x0 0x3d1c6000>;
		linux,initrd-end = <0x0 0x3dec11b4>;
	};

	aux_ref_clk {
		compatible = "fixed-clock";
		#clock-cells = <0x0>;
		phandle = <0x3f>;
		u-boot,dm-pre-reloc;
		clock-frequency = <0x19bfcc0>;
		linux,phandle = <0x3f>;
	};

	clkc {
		compatible = "xlnx,zynqmp-clkc";
		clocks = <0x3c 0x3d 0x3e 0x3f 0x40>;
		clock-names = "pss_ref_clk", "video_clk", "pss_alt_ref_clk", "aux_ref_clk", "gt_crx_ref_clk";
		#clock-cells = <0x1>;
		phandle = <0x3>;
		u-boot,dm-pre-reloc;
		clock-output-names = "iopll", "rpll", "apll", "dpll", "vpll", "iopll_to_fpd", "rpll_to_fpd", "apll_to_lpd", "dpll_to_lpd", "vpll_to_lpd", "acpu", "acpu_half", "dbf_fpd", "dbf_lpd", "dbg_trace", "dbg_tstmp", "dp_video_ref", "dp_audio_ref", "dp_stc_ref", "gdma_ref", "dpdma_ref", "ddr_ref", "sata_ref", "pcie_ref", "gpu_ref", "gpu_pp0_ref", "gpu_pp1_ref", "topsw_main", "topsw_lsbus", "gtgref0_ref", "lpd_switch", "lpd_lsbus", "usb0_bus_ref", "usb1_bus_ref", "usb3_dual_ref", "usb0", "usb1", "cpu_r5", "cpu_r5_core", "csu_spb", "csu_pll", "pcap", "iou_switch", "gem_tsu_ref", "gem_tsu", "gem0_ref", "gem1_ref", "gem2_ref", "gem3_ref", "gem0_tx", "gem1_tx", "gem2_tx", "gem3_tx", "qspi_ref", "sdio0_ref", "sdio1_ref", "uart0_ref", "uart1_ref", "spi0_ref", "spi1_ref", "nand_ref", "i2c0_ref", "i2c1_ref", "can0_ref", "can1_ref", "can0", "can1", "dll_ref", "adma_ref", "timestamp_ref", "ams_ref", "pl0", "pl1", "pl2", "pl3", "wdt";
		linux,phandle = <0x3>;
	};

	zynqmp_rsa {
		compatible = "xlnx,zynqmp-rsa";
	};

	edac {
		compatible = "arm,cortex-a53-edac";
	};

	dp_snd_pcm1 {
		compatible = "xlnx,dp-snd-pcm";
		status = "disabled";
		dma-names = "tx";
		phandle = <0x7>;
		dmas = <0x9 0x5>;
		linux,phandle = <0x7>;
	};

	fclk2 {
		compatible = "xlnx,fclk";
		clocks = <0x3 0x49>;
		status = "disabled";
	};

	timer {
		compatible = "arm,armv8-timer";
		interrupt-parent = <0x4>;
		interrupts = <0x1 0xd 0xf08 0x1 0xe 0xf08 0x1 0xb 0xf08 0x1 0xa 0xf08>;
	};

	fclk0 {
		compatible = "xlnx,fclk";
		clocks = <0x3 0x47>;
		status = "disabled";
	};

	sha384 {
		compatible = "xlnx,zynqmp-keccak-384";
	};

	reset-controller {
		compatible = "xlnx,zynqmp-reset";
		#reset-cells = <0x1>;
		phandle = <0x27>;
		linux,phandle = <0x27>;
	};

	pss_alt_ref_clk {
		compatible = "fixed-clock";
		#clock-cells = <0x0>;
		phandle = <0x3e>;
		u-boot,dm-pre-reloc;
		clock-frequency = <0x0>;
		linux,phandle = <0x3e>;
	};

	dp_snd_codec0 {
		compatible = "xlnx,dp-snd-codec";
		clocks = <0x3 0x11>;
		clock-names = "aud_clk";
		status = "disabled";
		phandle = <0x8>;
		linux,phandle = <0x8>;
	};

	pmu {
		compatible = "arm,armv8-pmuv3";
		interrupt-parent = <0x4>;
		interrupts = <0x0 0x8f 0x4 0x0 0x90 0x4 0x0 0x91 0x4 0x0 0x92 0x4>;
	};

	cpus {
		#address-cells = <0x1>;
		#size-cells = <0x0>;

		cpu@3 {
			compatible = "arm,cortex-a53", "arm,armv8";
			cpu-idle-states = <0x2>;
			device_type = "cpu";
			enable-method = "psci";
			operating-points-v2 = <0x1>;
			reg = <0x3>;
		};

		idle-states {
			entry-method = "arm,psci";

			cpu-sleep-0 {
				compatible = "arm,idle-state";
				arm,psci-suspend-param = <0x40000000>;
				phandle = <0x2>;
				exit-latency-us = <0x258>;
				entry-latency-us = <0x12c>;
				local-timer-stop;
				linux,phandle = <0x2>;
				min-residency-us = <0x2710>;
			};
		};

		cpu@1 {
			compatible = "arm,cortex-a53", "arm,armv8";
			cpu-idle-states = <0x2>;
			device_type = "cpu";
			enable-method = "psci";
			operating-points-v2 = <0x1>;
			reg = <0x1>;
		};

		cpu@2 {
			compatible = "arm,cortex-a53", "arm,armv8";
			cpu-idle-states = <0x2>;
			device_type = "cpu";
			enable-method = "psci";
			operating-points-v2 = <0x1>;
			reg = <0x2>;
		};

		cpu@0 {
			compatible = "arm,cortex-a53", "arm,armv8";
			clocks = <0x3 0xa>;
			cpu-idle-states = <0x2>;
			device_type = "cpu";
			enable-method = "psci";
			operating-points-v2 = <0x1>;
			reg = <0x0>;
		};
	};

	pss_ref_clk {
		compatible = "fixed-clock";
		#clock-cells = <0x0>;
		phandle = <0x3c>;
		u-boot,dm-pre-reloc;
		clock-frequency = <0x2faf080>;
		linux,phandle = <0x3c>;
	};
};
